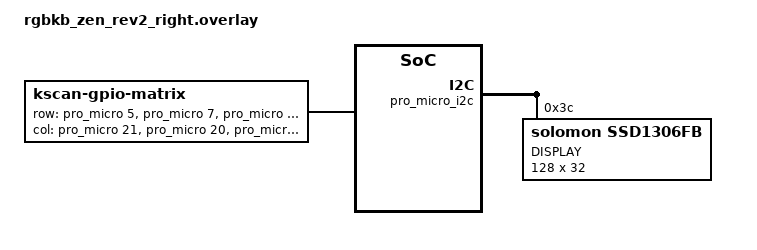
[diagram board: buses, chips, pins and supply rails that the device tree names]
/*
 * Copyright (c) 2022 The ZMK Contributors
 *
 * SPDX-License-Identifier: MIT
 */

#include "rgbkb_zen_rev2.dtsi"

&pro_micro_i2c {
	status = "okay";

	oled: ssd1306@3c {
		compatible = "solomon,ssd1306fb";
		reg = <0x3c>;
		label = "DISPLAY";
		width = <128>;
		height = <32>;
		segment-offset = <0>;
		page-offset = <0>;
		display-offset = <0>;
		multiplex-ratio = <31>;
		segment-remap;
		com-invdir;
		com-sequential;
		prechargep = <0x22>;
	};
};

/ {
	chosen {
		zmk,kscan = &kscan;
		zephyr,display = &oled;
	};

	kscan: kscan {
		compatible = "zmk,kscan-gpio-matrix";

		label = "KSCAN";
		diode-direction = "col2row";

		row-gpios
			= <&pro_micro 5 (GPIO_PULL_DOWN | GPIO_ACTIVE_HIGH)>
			, <&pro_micro 7 (GPIO_PULL_DOWN | GPIO_ACTIVE_HIGH)>
			, <&pro_micro 9 (GPIO_PULL_DOWN | GPIO_ACTIVE_HIGH)>
			, <&pro_micro 6 (GPIO_PULL_DOWN | GPIO_ACTIVE_HIGH)>
			, <&pro_micro 8 (GPIO_PULL_DOWN | GPIO_ACTIVE_HIGH)>
			;

		col-gpios 
			= <&pro_micro 21 GPIO_ACTIVE_HIGH>
			, <&pro_micro 20 GPIO_ACTIVE_HIGH>
			, <&pro_micro 19 GPIO_ACTIVE_HIGH>
			, <&pro_micro 18 GPIO_ACTIVE_HIGH>
			, <&pro_micro 14 GPIO_ACTIVE_HIGH>
			, <&pro_micro 15 GPIO_ACTIVE_HIGH>
			, <&pro_micro 16 GPIO_ACTIVE_HIGH>
			;
	};
};

&default_transform {
	col-offset = <7>;
};
